# LargeDummyDevice register map
File version: 1.0
Registers are 32-bit, read-write, no defined reset value unless marked. A register's access mark holds for its fields unless they carry their own. Offsets are from the block's base; [hi:lo] are bit positions.

## PERIPHERAL_8
Base 0x40007000
0x04 REG_1 — Register 1
  [30:29] FIELD_6, [28:27] FIELD_23, [30:26] FIELD_16, [23:22] FIELD_8, [26:22] FIELD_12, [21] FIELD_13, [22:21] FIELD_17, [24:20] FIELD_1, [23:20] FIELD_15, [22:20] FIELD_21, [20:19] FIELD_9, [23:19] FIELD_11, [19:18] FIELD_14, [18:17] FIELD_19, [15:14] FIELD_18, [11] FIELD_3, [13:11] FIELD_20, [14:10] FIELD_5, [11:7] FIELD_10, [7:4] FIELD_22, [4:3] FIELD_7, [4:2] FIELD_4, [2] FIELD_24, [0] FIELD_2
0x08 REG_2 — Register 2
  [30:29] FIELD_2, [29] FIELD_7, [27] FIELD_10, [26:25] FIELD_1, [25] FIELD_25, [26:25] FIELD_27, [27:24] FIELD_17, [23] FIELD_18, [27:23] FIELD_22, [23] FIELD_28, [23:22] FIELD_13, [22] FIELD_19, [21:20] FIELD_16, [17:15] FIELD_4, [17:13] FIELD_5, [15:13] FIELD_9, [16:13] FIELD_23, [15:13] FIELD_24, [14:11] FIELD_20, [10:7] FIELD_26, [9:5] FIELD_11, [5:4] FIELD_8, [6:4] FIELD_14, [7:3] FIELD_3, [6:3] FIELD_12, [2] FIELD_15, [1:0] FIELD_6, [3:0] FIELD_21
0x0C REG_3 — Register 3
  [31] FIELD_9, [30] FIELD_2, [31:29] FIELD_25, [28] FIELD_8, [29:27] FIELD_4, [28:27] FIELD_11, [31:27] FIELD_20, [29:25] FIELD_6, [27:23] FIELD_10, [23:20] FIELD_12, [22:19] FIELD_17, [22:19] FIELD_21, [18:15] FIELD_18, [16:14] FIELD_3, [18:14] FIELD_23, [17:13] FIELD_13, [14:13] FIELD_19, [13:11] FIELD_7, [10:8] FIELD_1, [10:8] FIELD_14, [9:7] FIELD_16, [9:7] FIELD_22, [9:6] FIELD_5, [7:3] FIELD_24, [2:0] FIELD_15
0x10 REG_4 — Register 4
  [29:28] FIELD_5, [26:25] FIELD_2, [20:17] FIELD_4, [18:17] FIELD_6, [11:7] FIELD_3, [4:3] FIELD_1
0x14 REG_5 — Register 5
  [35:31] FIELD_21, [33:29] FIELD_10, [32:29] FIELD_18, [29:27] FIELD_17, [29:27] FIELD_24, [27:23] FIELD_14, [25:23] FIELD_19, [27:23] FIELD_23, [22:18] FIELD_5, [18:17] FIELD_20, [19:16] FIELD_15, [16:14] FIELD_22, [15:13] FIELD_2, [16:12] FIELD_6, [11:10] FIELD_13, [11:9] FIELD_12, [8:6] FIELD_16, [7:5] FIELD_3, [7:4] FIELD_7, [7:4] FIELD_11, [5:3] FIELD_1, [7:3] FIELD_9, [5:3] FIELD_25, [4:2] FIELD_4, [5:2] FIELD_8, [1:0] FIELD_26
0x18 REG_6 — Register 6
  [35:31] FIELD_7, [32:31] FIELD_17, [28:27] FIELD_3, [24] FIELD_12, [26:24] FIELD_14, [25:24] FIELD_28, [21] FIELD_18, [21] FIELD_29, [23:20] FIELD_1, [22:20] FIELD_8, [21:19] FIELD_20, [18] FIELD_23, [18] FIELD_24, [20:17] FIELD_5, [16:15] FIELD_21, [14:13] FIELD_19, [14:12] FIELD_11, [15:12] FIELD_16, [9] FIELD_27, [8] FIELD_26, [10:7] FIELD_25, [7:6] FIELD_9, [5] FIELD_4, [6:4] FIELD_15, [5:4] FIELD_22, [3] FIELD_2, [6:2] FIELD_13, [4:1] FIELD_6, [3:1] FIELD_10
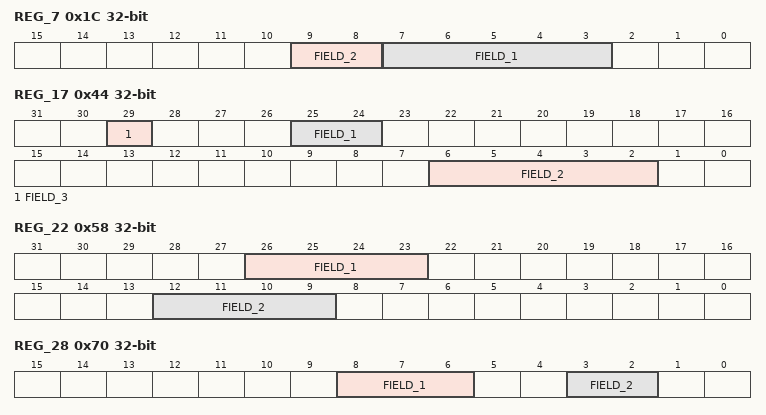
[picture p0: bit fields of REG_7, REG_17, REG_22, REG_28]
0x1C REG_7 — Register 7
  [9:8] FIELD_2, [7:3] FIELD_1
0x20 REG_8 — Register 8
  [33:31] FIELD_1, [29:28] FIELD_9, [28] FIELD_10, [30:28] FIELD_22, [28:27] FIELD_13, [30:27] FIELD_14, [26] FIELD_7, [27:25] FIELD_2, [25:24] FIELD_16, [24:20] FIELD_15, [20:17] FIELD_21, [18:15] FIELD_4, [19:15] FIELD_19, [14:13] FIELD_23, [12:10] FIELD_17, [13:9] FIELD_3, [13:9] FIELD_18, [9:8] FIELD_5, [11:8] FIELD_8, [12:8] FIELD_12, [6:5] FIELD_20, [5:2] FIELD_6, [6:2] FIELD_11
0x24 REG_9 — Register 9
  [32:31] FIELD_9, [31] FIELD_15, [34:30] FIELD_21, [30:29] FIELD_14, [32:28] FIELD_7, [30:27] FIELD_11, [26:23] FIELD_6, [27:23] FIELD_13, [23:22] FIELD_10, [23:21] FIELD_19, [21:18] FIELD_4, [18:14] FIELD_12, [17:13] FIELD_1, [12] FIELD_18, [12:9] FIELD_23, [12:8] FIELD_2, [12:8] FIELD_3, [10:8] FIELD_17, [9:5] FIELD_8, [5] FIELD_16, [3] FIELD_5, [4:3] FIELD_22, [4:1] FIELD_20
0x28 REG_10 — Register 10
  [30:28] FIELD_11, [28] FIELD_12, [28:27] FIELD_13, [30:27] FIELD_17, [27:26] FIELD_3, [28:24] FIELD_16, [27:23] FIELD_1, [26:22] FIELD_8, [25:22] FIELD_15, [23:21] FIELD_4, [23:20] FIELD_10, [19] FIELD_6, [20:18] FIELD_2, [15:13] FIELD_5, [12:11] FIELD_14, [13:9] FIELD_19, [7] FIELD_18, [4] FIELD_7, [4] FIELD_9
0x2C REG_11 — Register 11
  [31] FIELD_4, [30:29] FIELD_5, [25:21] FIELD_1, [8:7] FIELD_2, [2] FIELD_6, [2:1] FIELD_3
0x30 REG_12 — Register 12
  [27] FIELD_9, [27:25] FIELD_10, [29:25] FIELD_15, [23] FIELD_13, [21:20] FIELD_4, [19:15] FIELD_14, [13] FIELD_8, [15:12] FIELD_2, [12:11] FIELD_6, [10] FIELD_3, [13:9] FIELD_12, [7] FIELD_5, [7:5] FIELD_11, [4:1] FIELD_1, [1:0] FIELD_7, [1:0] FIELD_16
0x34 REG_13 — Register 13
  [31:27] FIELD_4, [27] FIELD_13, [25:24] FIELD_2, [19] FIELD_7, [21:18] FIELD_16, [16] FIELD_1, [18:14] FIELD_17, [12:10] FIELD_3, [10] FIELD_9, [12:10] FIELD_12, [13:10] FIELD_18, [9] FIELD_8, [8:6] FIELD_15, [8:5] FIELD_5, [9:5] FIELD_11, [8:5] FIELD_14, [3] FIELD_6, [1:0] FIELD_10
0x38 REG_14 — Register 14
  [35:31] FIELD_11, [32:29] FIELD_6, [26:25] FIELD_4, [24:23] FIELD_5, [26:22] FIELD_8, [24:20] FIELD_10, [18] FIELD_12, [15:14] FIELD_2, [7:5] FIELD_9, [8:4] FIELD_7, [6:3] FIELD_1, [4:0] FIELD_3
0x3C REG_15 — Register 15
  [31:29] FIELD_5, [28] FIELD_3, [27:23] FIELD_4, [27:23] FIELD_9, [22:20] FIELD_1, [21:19] FIELD_8, [18] FIELD_2, [9:5] FIELD_7, [5:3] FIELD_6
0x40 REG_16 — Register 16
  [31] FIELD_10, [35:31] FIELD_18, [31] FIELD_24, [32:29] FIELD_12, [30:28] FIELD_5, [28] FIELD_13, [31:28] FIELD_17, [29:27] FIELD_21, [27:25] FIELD_22, [26:24] FIELD_19, [22:21] FIELD_1, [23:21] FIELD_2, [22:21] FIELD_15, [20:17] FIELD_6, [21:17] FIELD_14, [17] FIELD_16, [19:16] FIELD_4, [18:14] FIELD_9, [11] FIELD_7, [12:11] FIELD_23, [14:10] FIELD_8, [10:8] FIELD_3, [9:7] FIELD_11, [7:6] FIELD_20, [8:4] FIELD_26, [3:0] FIELD_25
0x44 REG_17 — Register 17
  [29] FIELD_3, [25:24] FIELD_1, [6:2] FIELD_2
0x48 REG_18 — Register 18
  [35:31] FIELD_17, [30] FIELD_1, [29] FIELD_10, [32:29] FIELD_13, [31:27] FIELD_7, [28:24] FIELD_3, [24] FIELD_9, [23] FIELD_6, [22] FIELD_15, [20:19] FIELD_2, [17] FIELD_14, [12:11] FIELD_11, [11:10] FIELD_16, [8] FIELD_12, [6:5] FIELD_5, [4] FIELD_8, [4:1] FIELD_4
0x4C REG_19 — Register 19
  [31] FIELD_3, [33:31] FIELD_25, [30] FIELD_20, [29:26] FIELD_16, [28:26] FIELD_19, [25:24] FIELD_21, [22] FIELD_12, [21] FIELD_7, [22:21] FIELD_9, [22:19] FIELD_18, [20:19] FIELD_24, [21:18] FIELD_6, [16] FIELD_14, [15:14] FIELD_27, [15:13] FIELD_22, [12] FIELD_11, [14:10] FIELD_23, [14:10] FIELD_26, [11:9] FIELD_13, [10:8] FIELD_2, [11:8] FIELD_15, [8:7] FIELD_5, [6:5] FIELD_1, [5] FIELD_4, [6:5] FIELD_8, [7:5] FIELD_10, [2] FIELD_17
0x50 REG_20 — Register 20
  [34:30] FIELD_2, [28] FIELD_5, [32:28] FIELD_17, [29:27] FIELD_9, [28:26] FIELD_7, [27:26] FIELD_20, [28:25] FIELD_10, [27:23] FIELD_3, [26:22] FIELD_1, [25:21] FIELD_6, [21:20] FIELD_14, [15] FIELD_16, [17:15] FIELD_19, [16:14] FIELD_15, [14:13] FIELD_12, [12:11] FIELD_13, [11:8] FIELD_18, [8:6] FIELD_11, [5:4] FIELD_21, [4] FIELD_22, [5:2] FIELD_4, [1] FIELD_8
0x54 REG_21 — Register 21
  [29:26] FIELD_11, [28:25] FIELD_10, [24] FIELD_4, [24:23] FIELD_8, [26:23] FIELD_9, [23:20] FIELD_16, [22:19] FIELD_12, [21:18] FIELD_1, [16] FIELD_3, [18:15] FIELD_14, [15] FIELD_15, [14] FIELD_13, [14:11] FIELD_2, [12:10] FIELD_7, [8:7] FIELD_6, [8:5] FIELD_5
0x58 REG_22 — Register 22
  [26:23] FIELD_1, [12:9] FIELD_2
0x5C REG_23 — Register 23
  [31] FIELD_13, [28:27] FIELD_20, [31:27] FIELD_24, [26:24] FIELD_14, [20] FIELD_8, [24:20] FIELD_12, [22:20] FIELD_22, [22:19] FIELD_7, [21:19] FIELD_11, [19] FIELD_17, [20:18] FIELD_21, [14] FIELD_4, [18:14] FIELD_6, [15:12] FIELD_3, [14:12] FIELD_23, [11] FIELD_15, [13:9] FIELD_1, [13:9] FIELD_19, [9:7] FIELD_18, [6] FIELD_10, [9:5] FIELD_2, [6:4] FIELD_5, [7:3] FIELD_9, [1:0] FIELD_16
0x60 REG_24 — Register 24
  [35:31] FIELD_4, [35:31] FIELD_8, [32:31] FIELD_10, [30:29] FIELD_5, [29:27] FIELD_24, [26] FIELD_12, [29:25] FIELD_6, [28:25] FIELD_9, [27:25] FIELD_28, [25:24] FIELD_11, [23] FIELD_26, [22:21] FIELD_17, [22:20] FIELD_16, [21:20] FIELD_25, [21:19] FIELD_7, [23:19] FIELD_22, [17:16] FIELD_1, [15] FIELD_2, [19:15] FIELD_14, [14] FIELD_3, [18:14] FIELD_21, [15:13] FIELD_18, [13:11] FIELD_23, [14:10] FIELD_27, [13:9] FIELD_13, [9] FIELD_15, [5] FIELD_20, [2] FIELD_19
0x64 REG_25 — Register 25
  [35:31] FIELD_2, [32:31] FIELD_13, [32:29] FIELD_21, [30:26] FIELD_9, [26:25] FIELD_12, [24:22] FIELD_5, [22:21] FIELD_10, [20] FIELD_6, [20:18] FIELD_7, [21:18] FIELD_16, [21:17] FIELD_1, [17] FIELD_14, [19:16] FIELD_11, [16:13] FIELD_15, [15:12] FIELD_20, [13:11] FIELD_8, [14:10] FIELD_22, [10:9] FIELD_3, [6] FIELD_19, [6:5] FIELD_4, [3:2] FIELD_18, [4:0] FIELD_17
0x68 REG_26 — Register 26
  [33:31] FIELD_13, [32:29] FIELD_1, [27:24] FIELD_2, [24] FIELD_9, [24:23] FIELD_8, [23:22] FIELD_17, [20:18] FIELD_12, [18] FIELD_21, [21:17] FIELD_4, [16] FIELD_19, [14:13] FIELD_10, [15:13] FIELD_18, [12] FIELD_5, [15:12] FIELD_6, [16:12] FIELD_20, [13:10] FIELD_7, [12:9] FIELD_3, [10:7] FIELD_15, [7:5] FIELD_11, [8:4] FIELD_14, [4:3] FIELD_16
0x6C REG_27 — Register 27
  [34:30] FIELD_25, [34:30] FIELD_26, [33:29] FIELD_16, [29] FIELD_23, [32:28] FIELD_3, [28:27] FIELD_8, [31:27] FIELD_12, [30:26] FIELD_5, [29:25] FIELD_10, [29:25] FIELD_30, [27:23] FIELD_2, [27:23] FIELD_13, [21] FIELD_22, [19:16] FIELD_7, [18:16] FIELD_14, [16] FIELD_28, [19:15] FIELD_19, [19:15] FIELD_31, [17:13] FIELD_11, [14:11] FIELD_18, [8:7] FIELD_29, [9:6] FIELD_15, [8:5] FIELD_1, [6:5] FIELD_24, [8:4] FIELD_20, [7:3] FIELD_9, [5:2] FIELD_4, [5:2] FIELD_6, [6:2] FIELD_21, [1] FIELD_17, [2:0] FIELD_27
0x70 REG_28 — Register 28
  [8:6] FIELD_1, [3:2] FIELD_2
0x74 REG_29 — Register 29
  [26:24] FIELD_4, [18:17] FIELD_3, [7:6] FIELD_1, [7:6] FIELD_2
0x78 REG_30 — Register 30
  [29:26] FIELD_6, [23] FIELD_1, [16:14] FIELD_5, [14:10] FIELD_2, [10:9] FIELD_4, [7:6] FIELD_7, [6:4] FIELD_3
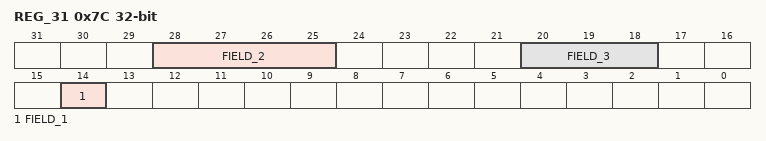
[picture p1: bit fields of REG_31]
0x7C REG_31 — Register 31
  [28:25] FIELD_2, [20:18] FIELD_3, [14] FIELD_1
0x80 REG_32 — Register 32
  [32:30] FIELD_17, [29:25] FIELD_1, [25] FIELD_18, [26:24] FIELD_4, [22] FIELD_10, [21] FIELD_6, [21] FIELD_11, [21:19] FIELD_16, [19:18] FIELD_13, [18:15] FIELD_9, [18:15] FIELD_15, [14:11] FIELD_5, [14:11] FIELD_7, [11:9] FIELD_2, [12:8] FIELD_12, [9:7] FIELD_8, [5] FIELD_14, [4:1] FIELD_3
0x84 REG_33 — Register 33
  [31] FIELD_2, [23] FIELD_8, [21:20] FIELD_3, [16:14] FIELD_7, [15:12] FIELD_4, [10] FIELD_6, [11:9] FIELD_5, [7:6] FIELD_1
0x88 REG_34 — Register 34
  [5:3] FIELD_1
0x8C REG_35 — Register 35
  [32:30] FIELD_1
0x90 REG_36 — Register 36
  [2:0] FIELD_1
0x94 REG_37 — Register 37
  [30] FIELD_17, [30:28] FIELD_11, [31:28] FIELD_18, [28:27] FIELD_26, [27:26] FIELD_24, [27:25] FIELD_1, [25] FIELD_12, [21] FIELD_5, [22:21] FIELD_8, [20] FIELD_3, [20:17] FIELD_10, [16:15] FIELD_7, [14] FIELD_23, [15:13] FIELD_6, [17:13] FIELD_21, [14:12] FIELD_16, [9:8] FIELD_15, [10:8] FIELD_27, [11:7] FIELD_4, [9:7] FIELD_25, [7] FIELD_28, [6] FIELD_13, [8:5] FIELD_22, [7:4] FIELD_9, [7:3] FIELD_2, [2:1] FIELD_14, [1] FIELD_19, [4:0] FIELD_20
0x98 REG_38 — Register 38
  [32:30] FIELD_6, [34:30] FIELD_15, [30:28] FIELD_16, [26:25] FIELD_3, [27:25] FIELD_11, [26:25] FIELD_13, [26:23] FIELD_9, [25:21] FIELD_7, [20:19] FIELD_8, [22:19] FIELD_14, [16:14] FIELD_10, [9] FIELD_1, [9] FIELD_12, [7] FIELD_4, [11:7] FIELD_5, [9:5] FIELD_2, [4] FIELD_19, [6:2] FIELD_17, [1] FIELD_18
0x9C REG_39 — Register 39
  [26] FIELD_5, [23:22] FIELD_9, [24:20] FIELD_2, [16] FIELD_1, [18:14] FIELD_4, [18:14] FIELD_6, [13:12] FIELD_7, [12:8] FIELD_3, [8:5] FIELD_8
0xA0 REG_40 — Register 40
  [28:26] FIELD_1, [23:20] FIELD_5, [21:17] FIELD_2, [20:17] FIELD_9, [11] FIELD_6, [13:9] FIELD_8, [6] FIELD_3, [6:4] FIELD_4, [4:1] FIELD_7
0xA4 REG_41 — Register 41
  [33:30] FIELD_12, [31:29] FIELD_1, [29] FIELD_17, [30:29] FIELD_23, [28] FIELD_2, [30:28] FIELD_24, [30:27] FIELD_9, [27] FIELD_20, [27:26] FIELD_6, [26:25] FIELD_3, [26:24] FIELD_7, [26:23] FIELD_15, [18] FIELD_14, [18:14] FIELD_8, [14:12] FIELD_10, [12:11] FIELD_21, [11:9] FIELD_25, [9:8] FIELD_5, [11:7] FIELD_13, [9:6] FIELD_11, [6:5] FIELD_16, [7:4] FIELD_18, [7:4] FIELD_19, [4] FIELD_22, [6:3] FIELD_4
0xA8 REG_42 — Register 42
  [34:30] FIELD_13, [30:28] FIELD_7, [27:26] FIELD_4, [26:24] FIELD_8, [24] FIELD_9, [24:23] FIELD_14, [25:23] FIELD_15, [22] FIELD_1, [21:18] FIELD_18, [16:15] FIELD_5, [15:14] FIELD_17, [16:13] FIELD_3, [14:13] FIELD_11, [16:12] FIELD_16, [10] FIELD_2, [13:10] FIELD_10, [11:7] FIELD_6, [4:3] FIELD_12, [4:1] FIELD_19
0xAC REG_43 — Register 43
  [35:31] FIELD_6, [31] FIELD_9, [34:30] FIELD_11, [31:27] FIELD_18, [26:25] FIELD_4, [26:24] FIELD_16, [27:24] FIELD_17, [24:20] FIELD_10, [24:20] FIELD_13, [16:13] FIELD_7, [16:13] FIELD_14, [13:9] FIELD_15, [10:7] FIELD_2, [8:7] FIELD_12, [6:4] FIELD_3, [6:4] FIELD_8, [3] FIELD_5, [6:2] FIELD_1
0xB0 REG_44 — Register 44
  [34:30] FIELD_2, [17:14] FIELD_4, [17:13] FIELD_1, [4:3] FIELD_3
0xB4 REG_45 — Register 45
  [26:25] FIELD_4, [19] FIELD_5, [20:16] FIELD_1, [19:16] FIELD_6, [15:12] FIELD_2, [15:12] FIELD_9, [15:11] FIELD_8, [12:9] FIELD_11, [5] FIELD_3, [7:4] FIELD_7, [1] FIELD_10
0xB8 REG_46 — Register 46
  [25] FIELD_4, [7] FIELD_2, [2:1] FIELD_3, [4:0] FIELD_1
0xBC REG_47 — Register 47
  [32:31] FIELD_14, [29:28] FIELD_3, [30:28] FIELD_16, [26] FIELD_5, [28:25] FIELD_1, [27:25] FIELD_7, [25:22] FIELD_4, [25:21] FIELD_21, [19:18] FIELD_18, [22:18] FIELD_23, [21:17] FIELD_20, [21:17] FIELD_25, [16:15] FIELD_13, [15:14] FIELD_19, [17:13] FIELD_8, [15:12] FIELD_10, [13:10] FIELD_6, [11:10] FIELD_22, [12:10] FIELD_24, [8] FIELD_12, [7] FIELD_2, [9:6] FIELD_11, [7:3] FIELD_15, [5:2] FIELD_9, [3:1] FIELD_17
